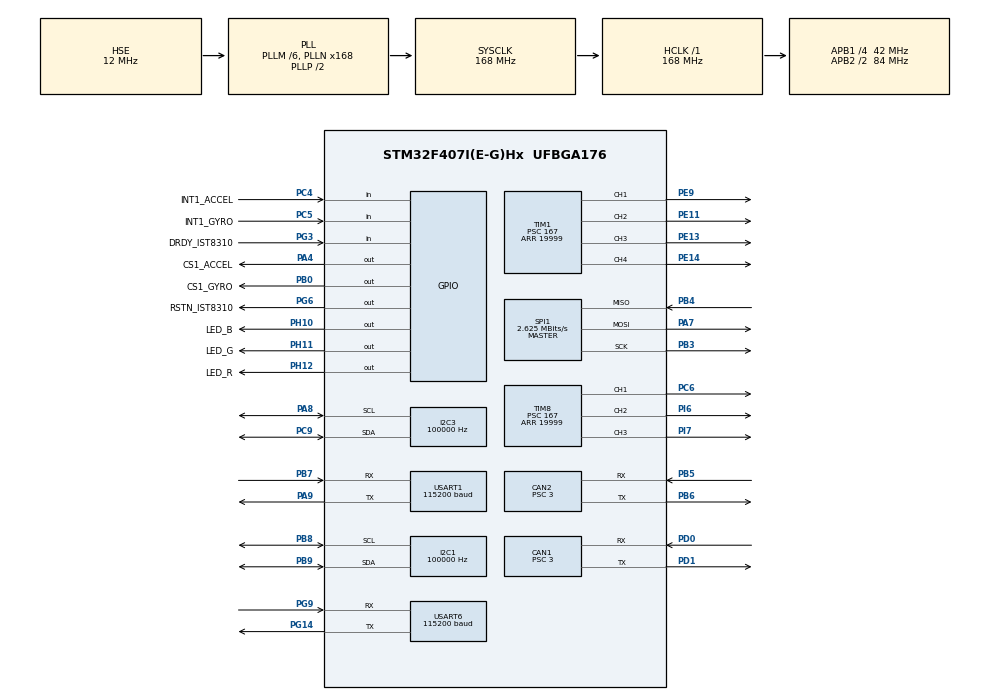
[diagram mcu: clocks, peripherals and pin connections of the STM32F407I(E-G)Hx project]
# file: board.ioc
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CAN1.AutoBusOff=ENABLE
CAN1.AutoRetransmission=ENABLE
CAN1.BS1=CAN_BS1_10TQ
CAN1.BS2=CAN_BS2_3TQ
CAN1.CalculateBaudRate=1000000
CAN1.CalculateTimeQuantum=71.42857142857143
CAN1.Mode=CAN_MODE_NORMAL
CAN1.Prescaler=3
CAN1.SJW=CAN_SJW_1TQ
CAN2.AutoBusOff=ENABLE
CAN2.AutoRetransmission=ENABLE
CAN2.BS1=CAN_BS1_10TQ
CAN2.BS2=CAN_BS2_3TQ
CAN2.CalculateBaudRate=1000000
CAN2.CalculateTimeQuantum=71.42857142857143
CAN2.Mode=CAN_MODE_NORMAL
CAN2.Prescaler=3
CAN2.SJW=CAN_SJW_1TQ
Dma.Request0=USART1_RX
Dma.Request1=USART1_TX
Dma.Request2=USART6_RX
Dma.Request3=USART6_TX
Dma.USART1_RX.0.Direction=DMA_PERIPH_TO_MEMORY
Dma.USART1_RX.0.FIFOMode=DMA_FIFOMODE_DISABLE
Dma.USART1_RX.0.Instance=DMA2_Stream2
Dma.USART1_RX.0.MemDataAlignment=DMA_MDATAALIGN_BYTE
Dma.USART1_RX.0.MemInc=DMA_MINC_ENABLE
Dma.USART1_RX.0.Mode=DMA_NORMAL
Dma.USART1_RX.0.PeriphDataAlignment=DMA_PDATAALIGN_BYTE
Dma.USART1_RX.0.PeriphInc=DMA_PINC_DISABLE
Dma.USART1_RX.0.Priority=DMA_PRIORITY_HIGH
Dma.USART1_TX.1.Direction=DMA_MEMORY_TO_PERIPH
Dma.USART1_TX.1.FIFOMode=DMA_FIFOMODE_DISABLE
Dma.USART1_TX.1.Instance=DMA2_Stream7
Dma.USART1_TX.1.MemDataAlignment=DMA_MDATAALIGN_BYTE
Dma.USART1_TX.1.MemInc=DMA_MINC_ENABLE
Dma.USART1_TX.1.Mode=DMA_NORMAL
Dma.USART1_TX.1.PeriphDataAlignment=DMA_PDATAALIGN_BYTE
Dma.USART1_TX.1.PeriphInc=DMA_PINC_DISABLE
Dma.USART1_TX.1.Priority=DMA_PRIORITY_MEDIUM
Dma.USART6_RX.2.Direction=DMA_PERIPH_TO_MEMORY
Dma.USART6_RX.2.FIFOMode=DMA_FIFOMODE_DISABLE
Dma.USART6_RX.2.Instance=DMA2_Stream1
Dma.USART6_RX.2.MemDataAlignment=DMA_MDATAALIGN_BYTE
Dma.USART6_RX.2.MemInc=DMA_MINC_ENABLE
Dma.USART6_RX.2.Mode=DMA_NORMAL
Dma.USART6_RX.2.PeriphDataAlignment=DMA_PDATAALIGN_BYTE
Dma.USART6_RX.2.PeriphInc=DMA_PINC_DISABLE
Dma.USART6_RX.2.Priority=DMA_PRIORITY_HIGH
Dma.USART6_TX.3.Direction=DMA_MEMORY_TO_PERIPH
Dma.USART6_TX.3.FIFOMode=DMA_FIFOMODE_DISABLE
Dma.USART6_TX.3.Instance=DMA2_Stream6
Dma.USART6_TX.3.MemDataAlignment=DMA_MDATAALIGN_BYTE
Dma.USART6_TX.3.MemInc=DMA_MINC_ENABLE
Dma.USART6_TX.3.Mode=DMA_NORMAL
Dma.USART6_TX.3.PeriphDataAlignment=DMA_PDATAALIGN_BYTE
Dma.USART6_TX.3.PeriphInc=DMA_PINC_DISABLE
Dma.USART6_TX.3.Priority=DMA_PRIORITY_MEDIUM
I2C1.AddressingMode=I2C_ADDRESSINGMODE_7BIT
I2C1.ClockSpeed=100000
I2C1.DualAddressMode=I2C_DUALADDRESS_DISABLE
I2C1.GeneralCallMode=I2C_GENERALCALL_DISABLE
I2C1.I2C_Mode=I2C_Standard
I2C1.NoStretchMode=I2C_NOSTRETCH_DISABLE
I2C1.OwnAddress1=0
I2C3.AddressingMode=I2C_ADDRESSINGMODE_7BIT
I2C3.ClockSpeed=100000
I2C3.DualAddressMode=I2C_DUALADDRESS_DISABLE
I2C3.GeneralCallMode=I2C_GENERALCALL_DISABLE
I2C3.I2C_Mode=I2C_Standard
I2C3.NoStretchMode=I2C_NOSTRETCH_DISABLE
I2C3.OwnAddress1=0
Mcu.Family=STM32F4
Mcu.Name=STM32F407I(E-G)Hx
Mcu.Package=UFBGA176
NVIC.CAN1_RX0_IRQn=true\:6\:0\:false\:false\:true\:false\:true\:true
NVIC.CAN2_RX0_IRQn=true\:6\:0\:false\:false\:true\:false\:true\:true
NVIC.DMA2_Stream1_IRQn=true\:6\:0\:false\:false\:true\:false\:true\:true
NVIC.DMA2_Stream2_IRQn=true\:6\:0\:false\:false\:true\:false\:true\:true
NVIC.DMA2_Stream6_IRQn=true\:6\:0\:false\:false\:true\:false\:true\:true
NVIC.DMA2_Stream7_IRQn=true\:6\:0\:false\:false\:true\:false\:true\:true
NVIC.PriorityGroup=NVIC_PRIORITYGROUP_4
NVIC.TIM6_DAC_IRQn=true\:15\:0\:false\:false\:true\:false\:true\:true
NVIC.USART1_IRQn=true\:6\:0\:false\:false\:true\:false\:true\:true
NVIC.USART6_IRQn=true\:6\:0\:false\:false\:true\:false\:true\:true
PA13.Mode=Serial_Wire
PA13.Signal=SYS_JTMS-SWDIO
PA14.Mode=Serial_Wire
PA14.Signal=SYS_JTCK-SWCLK
PA4.GPIO_Label=CS1_ACCEL
PA4.GPIO_PuPd=GPIO_PULLUP
PA4.GPIO_Speed=GPIO_SPEED_FREQ_HIGH
PA4.PinState=GPIO_PIN_SET
PA4.Signal=GPIO_Output
PA7.Mode=Full_Duplex_Master
PA7.Signal=SPI1_MOSI
PA8.Mode=I2C
PA8.Signal=I2C3_SCL
PA9.Mode=Asynchronous
PA9.Signal=USART1_TX
PB0.GPIO_Label=CS1_GYRO
PB0.GPIO_PuPd=GPIO_PULLUP
PB0.GPIO_Speed=GPIO_SPEED_FREQ_HIGH
PB0.PinState=GPIO_PIN_SET
PB0.Signal=GPIO_Output
PB3.Mode=Full_Duplex_Master
PB3.Signal=SPI1_SCK
PB4.Mode=Full_Duplex_Master
PB4.Signal=SPI1_MISO
PB5.Mode=CAN_Activate
PB5.Signal=CAN2_RX
PB6.Mode=CAN_Activate
PB6.Signal=CAN2_TX
PB7.Mode=Asynchronous
PB7.Signal=USART1_RX
PB8.Mode=I2C
PB8.Signal=I2C1_SCL
PB9.Mode=I2C
PB9.Signal=I2C1_SDA
PC4.GPIO_Label=INT1_ACCEL
PC4.GPIO_PuPd=GPIO_NOPULL
PC4.Signal=GPIO_Input
PC5.GPIO_Label=INT1_GYRO
PC5.GPIO_PuPd=GPIO_NOPULL
PC5.Signal=GPIO_Input
PC6.Signal=S_TIM8_CH1
PC9.Mode=I2C
PC9.Signal=I2C3_SDA
PD0.Mode=CAN_Activate
PD0.Signal=CAN1_RX
PD1.Mode=CAN_Activate
PD1.Signal=CAN1_TX
PE11.Signal=S_TIM1_CH2
PE13.Signal=S_TIM1_CH3
PE14.Signal=S_TIM1_CH4
PE9.Signal=S_TIM1_CH1
PG14.Mode=Asynchronous
PG14.Signal=USART6_TX
PG3.GPIO_Label=DRDY_IST8310
PG3.GPIO_PuPd=GPIO_NOPULL
PG3.Signal=GPIO_Input
PG6.GPIO_Label=RSTN_IST8310
PG6.GPIO_PuPd=GPIO_NOPULL
PG6.GPIO_Speed=GPIO_SPEED_FREQ_LOW
PG6.PinState=GPIO_PIN_SET
PG6.Signal=GPIO_Output
PG9.Mode=Asynchronous
PG9.Signal=USART6_RX
PH0-OSC_IN.Mode=HSE-External-Oscillator
PH0-OSC_IN.Signal=RCC_OSC_IN
PH1-OSC_OUT.Mode=HSE-External-Oscillator
PH1-OSC_OUT.Signal=RCC_OSC_OUT
PH10.GPIO_Label=LED_B
PH10.GPIO_PuPd=GPIO_NOPULL
PH10.GPIO_Speed=GPIO_SPEED_FREQ_LOW
PH10.PinState=GPIO_PIN_SET
PH10.Signal=GPIO_Output
PH11.GPIO_Label=LED_G
PH11.GPIO_PuPd=GPIO_NOPULL
PH11.GPIO_Speed=GPIO_SPEED_FREQ_LOW
PH11.PinState=GPIO_PIN_SET
PH11.Signal=GPIO_Output
PH12.GPIO_Label=LED_R
PH12.GPIO_PuPd=GPIO_NOPULL
PH12.GPIO_Speed=GPIO_SPEED_FREQ_LOW
PH12.PinState=GPIO_PIN_SET
PH12.Signal=GPIO_Output
PI6.Signal=S_TIM8_CH2
PI7.Signal=S_TIM8_CH3
ProjectManager.HeapSize=0x2000
ProjectManager.StackSize=0x2000
ProjectManager.TargetToolchain=CMake
RCC.48MHZClocksFreq_Value=48000000
RCC.AHBFreq_Value=168000000
RCC.APB1CLKDivider=RCC_HCLK_DIV4
RCC.APB1Freq_Value=42000000
RCC.APB1TimFreq_Value=84000000
RCC.APB2CLKDivider=RCC_HCLK_DIV2
RCC.APB2Freq_Value=84000000
RCC.APB2TimFreq_Value=168000000
RCC.CortexFreq_Value=168000000
RCC.HCLKFreq_Value=168000000
RCC.HSE_VALUE=12000000
RCC.HSI_VALUE=16000000
RCC.LSE_VALUE=32768
RCC.PLLM=6
RCC.PLLN=168
RCC.PLLP=RCC_PLLP_DIV2
RCC.PLLQ=7
RCC.PLLSourceVirtual=RCC_PLLSOURCE_HSE
RCC.SYSCLKFreq_VALUE=168000000
RCC.SYSCLKSource=RCC_SYSCLKSOURCE_PLLCLK
RCC.VCOOutputFreq_Value=336000000
SH.S_TIM1_CH1.0=TIM1_CH1,PWM Generation1 CH1
SH.S_TIM1_CH2.0=TIM1_CH2,PWM Generation2 CH2
SH.S_TIM1_CH3.0=TIM1_CH3,PWM Generation3 CH3
SH.S_TIM1_CH4.0=TIM1_CH4,PWM Generation4 CH4
SH.S_TIM8_CH1.0=TIM8_CH1,PWM Generation1 CH1
SH.S_TIM8_CH2.0=TIM8_CH2,PWM Generation2 CH2
SH.S_TIM8_CH3.0=TIM8_CH3,PWM Generation3 CH3
SPI1.BaudRatePrescaler=SPI_BAUDRATEPRESCALER_32
SPI1.CLKPhase=SPI_PHASE_2EDGE
SPI1.CLKPolarity=SPI_POLARITY_HIGH
SPI1.CalculateBaudRate=2.625 MBits/s
SPI1.DataSize=SPI_DATASIZE_8BIT
SPI1.Direction=SPI_DIRECTION_2LINES
SPI1.FirstBit=SPI_FIRSTBIT_MSB
SPI1.Mode=SPI_MODE_MASTER
SPI1.NSS=SPI_NSS_SOFT
SPI1.VirtualType=VM_MASTER
TIM1.Channel-PWM\ Generation1\ CH1=TIM_CHANNEL_1
TIM1.Channel-PWM\ Generation2\ CH2=TIM_CHANNEL_2
TIM1.Channel-PWM\ Generation3\ CH3=TIM_CHANNEL_3
TIM1.Channel-PWM\ Generation4\ CH4=TIM_CHANNEL_4
TIM1.Period=19999
TIM1.Prescaler=167
TIM1.Pulse-PWM\ Generation1\ CH1=0
TIM1.Pulse-PWM\ Generation2\ CH2=0
TIM1.Pulse-PWM\ Generation3\ CH3=0
TIM1.Pulse-PWM\ Generation4\ CH4=0
TIM8.Channel-PWM\ Generation1\ CH1=TIM_CHANNEL_1
TIM8.Channel-PWM\ Generation2\ CH2=TIM_CHANNEL_2
TIM8.Channel-PWM\ Generation3\ CH3=TIM_CHANNEL_3
TIM8.Period=19999
TIM8.Prescaler=167
TIM8.Pulse-PWM\ Generation1\ CH1=0
TIM8.Pulse-PWM\ Generation2\ CH2=0
TIM8.Pulse-PWM\ Generation3\ CH3=0
USART1.BaudRate=115200
USART1.Mode=MODE_TX_RX
USART1.OverSampling=UART_OVERSAMPLING_16
USART1.Parity=PARITY_NONE
USART1.StopBits=STOPBITS_1
USART1.VirtualMode=VM_ASYNC
USART1.WordLength=WORDLENGTH_8B
USART6.BaudRate=115200
USART6.Mode=MODE_TX_RX
USART6.OverSampling=UART_OVERSAMPLING_16
USART6.Parity=PARITY_NONE
USART6.StopBits=STOPBITS_1
USART6.VirtualMode=VM_ASYNC
USART6.WordLength=WORDLENGTH_8B
VP_SYS_VS_tim6.Mode=TIM6
VP_TIM1_VS_ClockSourceINT.Mode=Internal
VP_TIM8_VS_ClockSourceINT.Mode=Internal
board=custom

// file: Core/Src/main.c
/* USER CODE BEGIN Header */
/**
  ******************************************************************************
  * @file           : main.c
  * @brief          : Main program body
  ******************************************************************************
  * @attention
  *
  * Copyright (c) 2026 STMicroelectronics.
  * All rights reserved.
  *
  * This software is licensed under terms that can be found in the LICENSE file
  * in the root directory of this software component.
  * If no LICENSE file comes with this software, it is provided AS-IS.
  *
  ******************************************************************************
  */
/* USER CODE END Header */
#include "main.h"
#include "can.h"
#include "dma.h"
#include "i2c.h"
#include "spi.h"
#include "tim.h"
#include "usart.h"
#include "gpio.h"

/* USER CODE BEGIN Includes */
#include "app_threadx.h"
#include "bsp.hpp"

/* USER CODE END Includes */

void SystemClock_Config(void);

int main(void)
{

  /* MCU Configuration--------------------------------------------------------*/

  /* Reset of all peripherals, Initializes the Flash interface and the Systick. */
  HAL_Init();

  /* Configure the system clock */
  SystemClock_Config();

  /* Initialize all configured peripherals */
  MX_GPIO_Init();
  MX_DMA_Init();
  MX_CAN1_Init();
  MX_CAN2_Init();
  MX_USART1_UART_Init();
  MX_USART6_UART_Init();
  MX_SPI1_Init();
  MX_I2C1_Init();
  MX_I2C3_Init();
  MX_TIM1_Init();
  MX_TIM8_Init();
  /* USER CODE BEGIN 2 */
  if (bsp_Init() != HAL_OK)
  {
    HAL_GPIO_WritePin(LED_R_GPIO_Port, LED_R_Pin, GPIO_PIN_RESET);
    Error_Handler();
  }
  app_threadx_start();

  /* USER CODE END 2 */

  /* Infinite loop */
  while (1)
  {

  }
}

void SystemClock_Config(void)
{
  RCC_OscInitTypeDef RCC_OscInitStruct = {0};
  RCC_ClkInitTypeDef RCC_ClkInitStruct = {0};

  /** Configure the main internal regulator output voltage
  */
  __HAL_RCC_PWR_CLK_ENABLE();
  __HAL_PWR_VOLTAGESCALING_CONFIG(PWR_REGULATOR_VOLTAGE_SCALE1);

  /** Initializes the RCC Oscillators according to the specified parameters
  * in the RCC_OscInitTypeDef structure.
  */
  RCC_OscInitStruct.OscillatorType = RCC_OSCILLATORTYPE_HSE;
  RCC_OscInitStruct.HSEState = RCC_HSE_ON;
  RCC_OscInitStruct.PLL.PLLState = RCC_PLL_ON;
  RCC_OscInitStruct.PLL.PLLSource = RCC_PLLSOURCE_HSE;
  RCC_OscInitStruct.PLL.PLLM = 6;
  RCC_OscInitStruct.PLL.PLLN = 168;
  RCC_OscInitStruct.PLL.PLLP = RCC_PLLP_DIV2;
  RCC_OscInitStruct.PLL.PLLQ = 7;
  if (HAL_RCC_OscConfig(&RCC_OscInitStruct) != HAL_OK)
  {
    Error_Handler();
  }

  /** Initializes the CPU, AHB and APB buses clocks
  */
  RCC_ClkInitStruct.ClockType = RCC_CLOCKTYPE_HCLK|RCC_CLOCKTYPE_SYSCLK
                              |RCC_CLOCKTYPE_PCLK1|RCC_CLOCKTYPE_PCLK2;
  RCC_ClkInitStruct.SYSCLKSource = RCC_SYSCLKSOURCE_PLLCLK;
  RCC_ClkInitStruct.AHBCLKDivider = RCC_SYSCLK_DIV1;
  RCC_ClkInitStruct.APB1CLKDivider = RCC_HCLK_DIV4;
  RCC_ClkInitStruct.APB2CLKDivider = RCC_HCLK_DIV2;

  if (HAL_RCC_ClockConfig(&RCC_ClkInitStruct, FLASH_LATENCY_5) != HAL_OK)
  {
    Error_Handler();
  }
}

void Error_Handler(void)
{
  __disable_irq();
  while (1)
  {
  }
}
